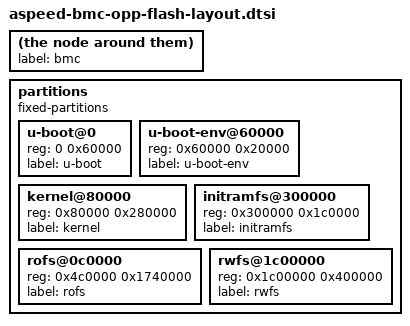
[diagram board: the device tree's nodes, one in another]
		label = "bmc";
		partitions {
				#address-cells = < 1 >;
				#size-cells = < 1 >;
				compatible = "fixed-partitions";
				u-boot@0 {
					reg = < 0 0x60000 >;
					label = "u-boot";
				};
				u-boot-env@60000 {
					reg = < 0x60000 0x20000 >;
					label = "u-boot-env";
				};
				kernel@80000 {
					reg = < 0x80000 0x280000 >;
					label = "kernel";
				};
				initramfs@300000 {
					reg = < 0x300000 0x1c0000 >;
					label = "initramfs";
				};
				rofs@0c0000 {
					reg = < 0x4c0000 0x1740000 >;
					label = "rofs";
				};
				rwfs@1c00000 {
					reg = < 0x1c00000 0x400000 >;
					label = "rwfs";
				};
		};
